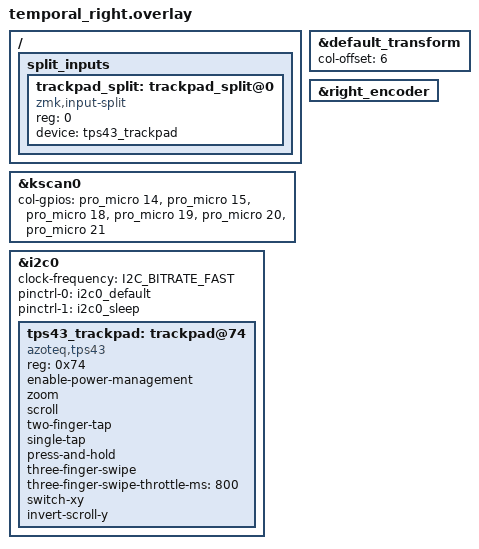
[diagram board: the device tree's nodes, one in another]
/*
 * Copyright (c) 2024 Curtis Bollinger
 *
 * SPDX-License-Identifier: MIT
 */

#include "temporal.dtsi"

&default_transform {
    col-offset = <6>;
};

&kscan0 {
    col-gpios
        = <&pro_micro 14 GPIO_ACTIVE_HIGH>  // col_inner
        , <&pro_micro 15 GPIO_ACTIVE_HIGH>  // col_index
        , <&pro_micro 18 GPIO_ACTIVE_HIGH>  // col_middle
        , <&pro_micro 19 GPIO_ACTIVE_HIGH>  // col_ring
        , <&pro_micro 20 GPIO_ACTIVE_HIGH>  // col_pinky (also encoder switch)
        , <&pro_micro 21 GPIO_ACTIVE_HIGH>  // col_extra
        ;
};

&right_encoder {
    status = "okay";
};






/*
 * Azoteq Trackpad Configuration
 *
 * decided to use the the geeksville module
 * README: https://github.com/geeksville/zmk_driver_azoteq
 *
 * Beekeeb Toucan 2 is an example implementation, but note it uses a seeed xiao
 * which has different i2c pins than the nice_nano. The Toucan 2 does not have a
 * dongle, but it uses right side trackpad
 * beekeeb/zmk-keyboard-toucan2/boards/shields/toucan/toucan_right.overlay
 *
 * This Temporal will use the default i2c pins as defined in zmk
 * zmkfirmware/zmk/app/module/boards/nicekeyboards/nice_nano/nice_nano-pinctrl.dtsi
 */

trackpad: &i2c0 {
    status = "okay";
    clock-frequency = <I2C_BITRATE_FAST>;
    pinctrl-0 = <&i2c0_default>;
    pinctrl-1 = <&i2c0_sleep>;
    pinctrl-names = "default", "sleep";

    tps43_trackpad: trackpad@74 {
        compatible = "azoteq,tps43";
        reg = <0x74>;
        status = "okay";

        //rdy-gpios = <&pro_micro 16 GPIO_ACTIVE_HIGH>;
        //rst-gpios = <&pro_micro 3 GPIO_ACTIVE_HIGH>;

        enable-power-management;

        zoom;
        scroll;
        two-finger-tap;
        single-tap;
        press-and-hold;
        three-finger-swipe;
        three-finger-swipe-throttle-ms = <800>;

        switch-xy;
        invert-scroll-y;
    };
};

/ {
    split_inputs {
        #address-cells = <1>;
        #size-cells = <0>;

        trackpad_split: trackpad_split@0 {
            compatible = "zmk,input-split";
            reg = <0>;
            device = <&tps43_trackpad>;
        };
    };
};

